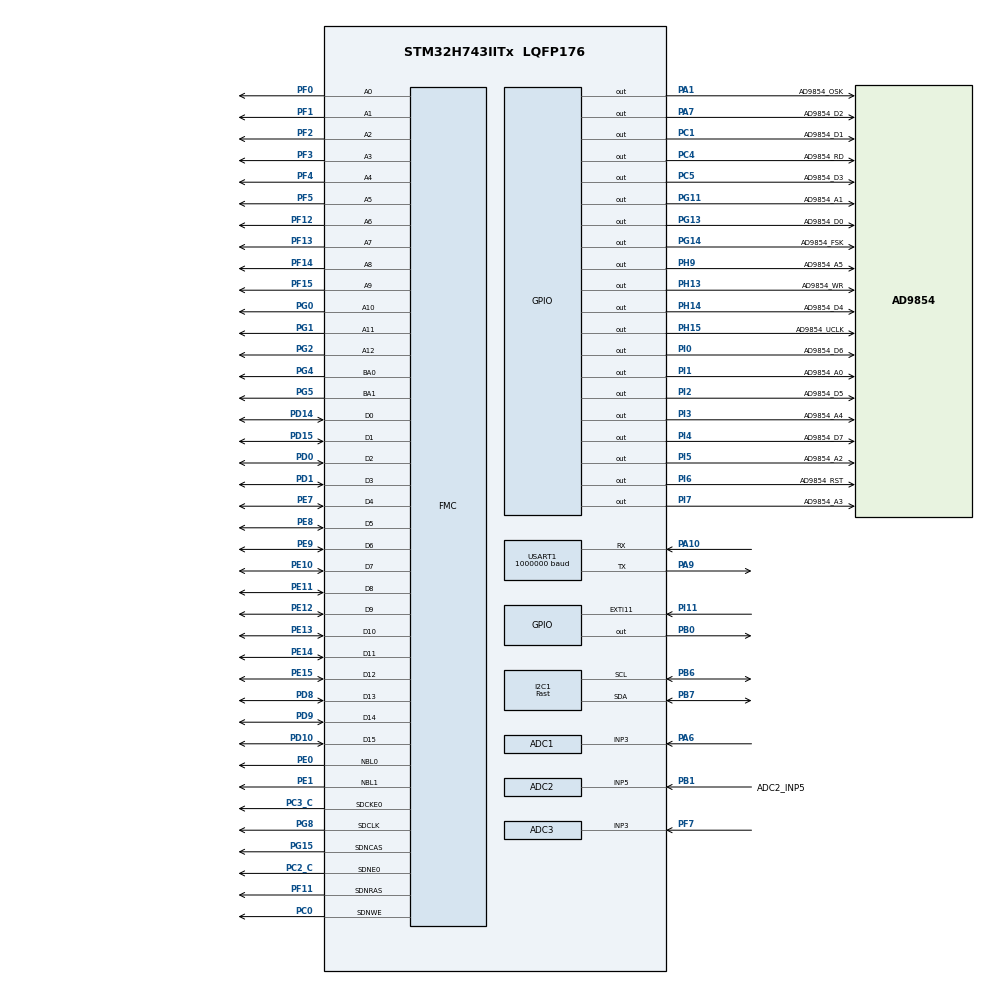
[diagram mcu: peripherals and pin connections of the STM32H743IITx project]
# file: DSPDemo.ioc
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ADC1.Channel-1\#ChannelRegularConversion=ADC_CHANNEL_3
ADC1.ConversionDataManagement=ADC_CONVERSIONDATA_DMA_CIRCULAR
ADC1.ExternalTrigConv=ADC_EXTERNALTRIG_EXT_IT11
ADC1.ExternalTrigConvEdge=ADC_EXTERNALTRIGCONVEDGE_RISING
ADC1.NbrOfConversion=1
ADC1.NbrOfConversionFlag=1
ADC1.OffsetNumber-1\#ChannelRegularConversion=ADC_OFFSET_NONE
ADC1.OffsetSignedSaturation-1\#ChannelRegularConversion=DISABLE
ADC1.Rank-1\#ChannelRegularConversion=1
ADC1.SamplingTime-1\#ChannelRegularConversion=ADC_SAMPLETIME_1CYCLE_5
ADC1.master=1
ADC2.Channel-0\#ChannelRegularConversion=ADC_CHANNEL_5
ADC2.ConversionDataManagement=ADC_CONVERSIONDATA_DMA_CIRCULAR
ADC2.NbrOfConversionFlag=1
ADC2.OffsetNumber-0\#ChannelRegularConversion=ADC_OFFSET_NONE
ADC2.OffsetSignedSaturation-0\#ChannelRegularConversion=DISABLE
ADC2.Overrun=ADC_OVR_DATA_PRESERVED
ADC2.Rank-0\#ChannelRegularConversion=1
ADC2.SamplingTime-0\#ChannelRegularConversion=ADC_SAMPLETIME_1CYCLE_5
ADC3.Channel-0\#ChannelRegularConversion=ADC_CHANNEL_3
ADC3.ConversionDataManagement=ADC_CONVERSIONDATA_DMA_CIRCULAR
ADC3.NbrOfConversionFlag=1
ADC3.OffsetNumber-0\#ChannelRegularConversion=ADC_OFFSET_NONE
ADC3.OffsetSignedSaturation-0\#ChannelRegularConversion=DISABLE
ADC3.Overrun=ADC_OVR_DATA_PRESERVED
ADC3.Rank-0\#ChannelRegularConversion=1
ADC3.SamplingTime-0\#ChannelRegularConversion=ADC_SAMPLETIME_1CYCLE_5
CORTEX_M7.AccessPermission-Cortex_Memory_Protection_Unit_Region0_Settings=MPU_REGION_FULL_ACCESS
CORTEX_M7.AccessPermission-Cortex_Memory_Protection_Unit_Region1_Settings=MPU_REGION_FULL_ACCESS
CORTEX_M7.AccessPermission-Cortex_Memory_Protection_Unit_Region2_Settings=MPU_REGION_FULL_ACCESS
CORTEX_M7.AccessPermission-Cortex_Memory_Protection_Unit_Region3_Settings=MPU_REGION_FULL_ACCESS
CORTEX_M7.AccessPermission-Cortex_Memory_Protection_Unit_Region4_Settings=MPU_REGION_FULL_ACCESS
CORTEX_M7.AccessPermission-Cortex_Memory_Protection_Unit_Region5_Settings=MPU_REGION_FULL_ACCESS
CORTEX_M7.AccessPermission-Cortex_Memory_Protection_Unit_Region6_Settings=MPU_REGION_FULL_ACCESS
CORTEX_M7.BaseAddress-Cortex_Memory_Protection_Unit_Region0_Settings=0x20000000
CORTEX_M7.BaseAddress-Cortex_Memory_Protection_Unit_Region1_Settings=0x24000000
CORTEX_M7.BaseAddress-Cortex_Memory_Protection_Unit_Region2_Settings=0x30000000
CORTEX_M7.BaseAddress-Cortex_Memory_Protection_Unit_Region3_Settings=0x38000000
CORTEX_M7.BaseAddress-Cortex_Memory_Protection_Unit_Region4_Settings=0x60000000
CORTEX_M7.BaseAddress-Cortex_Memory_Protection_Unit_Region5_Settings=0xC0000000
CORTEX_M7.BaseAddress-Cortex_Memory_Protection_Unit_Region6_Settings=0x80000000
CORTEX_M7.CPU_DCache=Enabled
CORTEX_M7.CPU_ICache=Enabled
CORTEX_M7.DisableExec-Cortex_Memory_Protection_Unit_Region6_Settings=MPU_INSTRUCTION_ACCESS_DISABLE
CORTEX_M7.Enable-Cortex_Memory_Protection_Unit_Region0_Settings=MPU_REGION_ENABLE
CORTEX_M7.Enable-Cortex_Memory_Protection_Unit_Region1_Settings=MPU_REGION_ENABLE
CORTEX_M7.Enable-Cortex_Memory_Protection_Unit_Region2_Settings=MPU_REGION_ENABLE
CORTEX_M7.Enable-Cortex_Memory_Protection_Unit_Region3_Settings=MPU_REGION_ENABLE
CORTEX_M7.Enable-Cortex_Memory_Protection_Unit_Region4_Settings=MPU_REGION_ENABLE
CORTEX_M7.Enable-Cortex_Memory_Protection_Unit_Region5_Settings=MPU_REGION_ENABLE
CORTEX_M7.Enable-Cortex_Memory_Protection_Unit_Region6_Settings=MPU_REGION_ENABLE
CORTEX_M7.Enable-Cortex_Memory_Protection_Unit_Region7_Settings=__NULL
CORTEX_M7.IsBufferable-Cortex_Memory_Protection_Unit_Region0_Settings=MPU_ACCESS_BUFFERABLE
CORTEX_M7.IsBufferable-Cortex_Memory_Protection_Unit_Region1_Settings=MPU_ACCESS_NOT_BUFFERABLE
CORTEX_M7.IsBufferable-Cortex_Memory_Protection_Unit_Region2_Settings=MPU_ACCESS_BUFFERABLE
CORTEX_M7.IsBufferable-Cortex_Memory_Protection_Unit_Region3_Settings=MPU_ACCESS_BUFFERABLE
CORTEX_M7.IsBufferable-Cortex_Memory_Protection_Unit_Region4_Settings=MPU_ACCESS_NOT_BUFFERABLE
CORTEX_M7.IsBufferable-Cortex_Memory_Protection_Unit_Region5_Settings=MPU_ACCESS_NOT_BUFFERABLE
CORTEX_M7.IsBufferable-Cortex_Memory_Protection_Unit_Region6_Settings=MPU_ACCESS_NOT_BUFFERABLE
CORTEX_M7.IsCacheable-Cortex_Memory_Protection_Unit_Region0_Settings=MPU_ACCESS_CACHEABLE
CORTEX_M7.IsCacheable-Cortex_Memory_Protection_Unit_Region1_Settings=MPU_ACCESS_CACHEABLE
CORTEX_M7.IsCacheable-Cortex_Memory_Protection_Unit_Region2_Settings=MPU_ACCESS_CACHEABLE
CORTEX_M7.IsCacheable-Cortex_Memory_Protection_Unit_Region3_Settings=MPU_ACCESS_CACHEABLE
CORTEX_M7.IsCacheable-Cortex_Memory_Protection_Unit_Region4_Settings=MPU_ACCESS_NOT_CACHEABLE
CORTEX_M7.IsCacheable-Cortex_Memory_Protection_Unit_Region5_Settings=MPU_ACCESS_NOT_CACHEABLE
CORTEX_M7.IsCacheable-Cortex_Memory_Protection_Unit_Region6_Settings=MPU_ACCESS_CACHEABLE
CORTEX_M7.IsShareable-Cortex_Memory_Protection_Unit_Region1_Settings=MPU_ACCESS_SHAREABLE
CORTEX_M7.IsShareable-Cortex_Memory_Protection_Unit_Region2_Settings=MPU_ACCESS_NOT_SHAREABLE
CORTEX_M7.MPU_Control=MPU_PRIVILEGED_DEFAULT
CORTEX_M7.Size-Cortex_Memory_Protection_Unit_Region0_Settings=MPU_REGION_SIZE_128KB
CORTEX_M7.Size-Cortex_Memory_Protection_Unit_Region1_Settings=MPU_REGION_SIZE_512KB
CORTEX_M7.Size-Cortex_Memory_Protection_Unit_Region2_Settings=MPU_REGION_SIZE_512KB
CORTEX_M7.Size-Cortex_Memory_Protection_Unit_Region3_Settings=MPU_REGION_SIZE_64KB
CORTEX_M7.Size-Cortex_Memory_Protection_Unit_Region4_Settings=MPU_REGION_SIZE_256MB
CORTEX_M7.Size-Cortex_Memory_Protection_Unit_Region5_Settings=MPU_REGION_SIZE_32MB
CORTEX_M7.Size-Cortex_Memory_Protection_Unit_Region6_Settings=MPU_REGION_SIZE_256MB
CORTEX_M7.default_mode_Activation=0
Dma.ADC1.0.Direction=DMA_PERIPH_TO_MEMORY
Dma.ADC1.0.EventEnable=DISABLE
Dma.ADC1.0.FIFOMode=DMA_FIFOMODE_DISABLE
Dma.ADC1.0.Instance=DMA1_Stream2
Dma.ADC1.0.MemDataAlignment=DMA_MDATAALIGN_HALFWORD
Dma.ADC1.0.MemInc=DMA_MINC_ENABLE
Dma.ADC1.0.Mode=DMA_CIRCULAR
Dma.ADC1.0.PeriphDataAlignment=DMA_PDATAALIGN_HALFWORD
Dma.ADC1.0.PeriphInc=DMA_PINC_DISABLE
Dma.ADC1.0.Polarity=HAL_DMAMUX_REQ_GEN_RISING
Dma.ADC1.0.Priority=DMA_PRIORITY_LOW
Dma.ADC1.0.RequestNumber=1
Dma.ADC1.0.SignalID=NONE
Dma.ADC1.0.SyncEnable=DISABLE
Dma.ADC1.0.SyncPolarity=HAL_DMAMUX_SYNC_NO_EVENT
Dma.ADC1.0.SyncRequestNumber=1
Dma.ADC1.0.SyncSignalID=NONE
Dma.ADC2.1.Direction=DMA_PERIPH_TO_MEMORY
Dma.ADC2.1.EventEnable=DISABLE
Dma.ADC2.1.FIFOMode=DMA_FIFOMODE_DISABLE
Dma.ADC2.1.Instance=DMA1_Stream3
Dma.ADC2.1.MemDataAlignment=DMA_MDATAALIGN_HALFWORD
Dma.ADC2.1.MemInc=DMA_MINC_ENABLE
Dma.ADC2.1.Mode=DMA_CIRCULAR
Dma.ADC2.1.PeriphDataAlignment=DMA_PDATAALIGN_HALFWORD
Dma.ADC2.1.PeriphInc=DMA_PINC_DISABLE
Dma.ADC2.1.Polarity=HAL_DMAMUX_REQ_GEN_RISING
Dma.ADC2.1.Priority=DMA_PRIORITY_LOW
Dma.ADC2.1.RequestNumber=1
Dma.ADC2.1.SignalID=NONE
Dma.ADC2.1.SyncEnable=DISABLE
Dma.ADC2.1.SyncPolarity=HAL_DMAMUX_SYNC_NO_EVENT
Dma.ADC2.1.SyncRequestNumber=1
Dma.ADC2.1.SyncSignalID=NONE
Dma.ADC3.2.Direction=DMA_PERIPH_TO_MEMORY
Dma.ADC3.2.EventEnable=DISABLE
Dma.ADC3.2.FIFOMode=DMA_FIFOMODE_DISABLE
Dma.ADC3.2.Instance=DMA1_Stream4
Dma.ADC3.2.MemDataAlignment=DMA_MDATAALIGN_HALFWORD
Dma.ADC3.2.MemInc=DMA_MINC_ENABLE
Dma.ADC3.2.Mode=DMA_CIRCULAR
Dma.ADC3.2.PeriphDataAlignment=DMA_PDATAALIGN_HALFWORD
Dma.ADC3.2.PeriphInc=DMA_PINC_DISABLE
Dma.ADC3.2.Polarity=HAL_DMAMUX_REQ_GEN_RISING
Dma.ADC3.2.Priority=DMA_PRIORITY_LOW
Dma.ADC3.2.RequestNumber=1
Dma.ADC3.2.SignalID=NONE
Dma.ADC3.2.SyncEnable=DISABLE
Dma.ADC3.2.SyncPolarity=HAL_DMAMUX_SYNC_NO_EVENT
Dma.ADC3.2.SyncRequestNumber=1
Dma.ADC3.2.SyncSignalID=NONE
Dma.Request0=ADC1
Dma.Request1=ADC2
Dma.Request2=ADC3
FMC.CASLatency1=FMC_SDRAM_CAS_LATENCY_3
FMC.ColumnBitsNumber1=FMC_SDRAM_COLUMN_BITS_NUM_9
FMC.ExitSelfRefreshDelay1=8
FMC.LoadToActiveDelay1=2
FMC.RCDDelay1=2
FMC.RPDelay1=2
FMC.ReadBurst1=FMC_SDRAM_RBURST_ENABLE
FMC.ReadPipeDelay1=FMC_SDRAM_RPIPE_DELAY_1
FMC.RowCycleDelay1=6
FMC.SDClockPeriod1=FMC_SDRAM_CLOCK_PERIOD_2
FMC.SelfRefreshTime1=6
FMC.WriteRecoveryTime1=4
I2C1.AddressingMode=I2C_ADDRESSINGMODE_7BIT
I2C1.I2C_Speed_Mode=I2C_Fast
I2C1.Timing=0x009034B6
Mcu.Family=STM32H7
Mcu.Name=STM32H743IITx
Mcu.Package=LQFP176
NVIC.DMA1_Stream2_IRQn=true\:1\:0\:true\:false\:true\:true\:true\:true
NVIC.DMA1_Stream3_IRQn=true\:1\:0\:true\:false\:true\:true\:true\:true
NVIC.DMA1_Stream4_IRQn=true\:1\:0\:true\:false\:true\:true\:true\:true
NVIC.EXTI15_10_IRQn=true\:1\:0\:true\:false\:true\:true\:true\:true
NVIC.PriorityGroup=NVIC_PRIORITYGROUP_4
NVIC.USART1_IRQn=true\:0\:0\:true\:false\:true\:true\:true\:true
PA1.GPIO_Label=AD9854_OSK
PA1.Signal=GPIO_Output
PA10.Mode=Asynchronous
PA10.Signal=USART1_RX
PA13\ (JTMS/SWDIO).Mode=Serial_Wire
PA13\ (JTMS/SWDIO).Signal=DEBUG_JTMS-SWDIO
PA14\ (JTCK/SWCLK).Mode=Serial_Wire
PA14\ (JTCK/SWCLK).Signal=DEBUG_JTCK-SWCLK
PA6.GPIO_Mode=GPIO_MODE_ANALOG
PA6.Signal=ADCx_INP3
PA7.GPIO_Label=AD9854_D2
PA7.Signal=GPIO_Output
PA9.Mode=Asynchronous
PA9.Signal=USART1_TX
PB0.GPIO_PuPd=GPIO_PULLUP
PB0.GPIO_Speed=GPIO_SPEED_FREQ_MEDIUM
PB0.PinState=GPIO_PIN_SET
PB0.Signal=GPIO_Output
PB1.GPIO_Label=ADC2_INP5
PB1.Signal=ADCx_INP5
PB12.Signal=SPI2_NSS
PB6.Mode=I2C
PB6.Signal=I2C1_SCL
PB7.GPIO_Speed=GPIO_SPEED_FREQ_LOW
PB7.Mode=I2C
PB7.Signal=I2C1_SDA
PC0.Signal=FMC_SDNWE
PC1.GPIO_Label=AD9854_D1
PC1.Signal=GPIO_Output
PC14-OSC32_IN\ (OSC32_IN).Mode=LSE-External-Oscillator
PC14-OSC32_IN\ (OSC32_IN).Signal=RCC_OSC32_IN
PC15-OSC32_OUT\ (OSC32_OUT).Mode=LSE-External-Oscillator
PC15-OSC32_OUT\ (OSC32_OUT).Signal=RCC_OSC32_OUT
PC2_C.Mode=SdramChipSelect1_1
PC2_C.Signal=FMC_SDNE0
PC3_C.Mode=SdramChipSelect1_1
PC3_C.Signal=FMC_SDCKE0
PC4.GPIO_Label=AD9854_RD
PC4.Signal=GPIO_Output
PC5.GPIO_Label=AD9854_D3
PC5.Signal=GPIO_Output
PD0.Signal=FMC_D2_DA2
PD1.Signal=FMC_D3_DA3
PD10.Signal=FMC_D15_DA15
PD14.Signal=FMC_D0_DA0
PD15.Signal=FMC_D1_DA1
PD8.Signal=FMC_D13_DA13
PD9.Signal=FMC_D14_DA14
PE0.Signal=FMC_NBL0
PE1.Signal=FMC_NBL1
PE10.Signal=FMC_D7_DA7
PE11.Signal=FMC_D8_DA8
PE12.Signal=FMC_D9_DA9
PE13.Signal=FMC_D10_DA10
PE14.Signal=FMC_D11_DA11
PE15.Signal=FMC_D12_DA12
PE7.Signal=FMC_D4_DA4
PE8.Signal=FMC_D5_DA5
PE9.Signal=FMC_D6_DA6
PF0.Signal=FMC_A0
PF1.Signal=FMC_A1
PF11.Signal=FMC_SDNRAS
PF12.Signal=FMC_A6
PF13.Signal=FMC_A7
PF14.Signal=FMC_A8
PF15.Signal=FMC_A9
PF2.Signal=FMC_A2
PF3.Signal=FMC_A3
PF4.Signal=FMC_A4
PF5.Signal=FMC_A5
PF7.Mode=IN3-Single-Ended
PF7.Signal=ADC3_INP3
PG0.Signal=FMC_A10
PG1.Signal=FMC_A11
PG11.GPIO_Label=AD9854_A1
PG11.Signal=GPIO_Output
PG13.GPIO_Label=AD9854_D0
PG13.Signal=GPIO_Output
PG14.GPIO_Label=AD9854_FSK
PG14.Signal=GPIO_Output
PG15.Signal=FMC_SDNCAS
PG2.Signal=FMC_A12
PG4.Signal=FMC_A14_BA0
PG5.Signal=FMC_A15_BA1
PG8.Signal=FMC_SDCLK
PH0-OSC_IN\ (PH0).Mode=HSE-External-Oscillator
PH0-OSC_IN\ (PH0).Signal=RCC_OSC_IN
PH1-OSC_OUT\ (PH1).Mode=HSE-External-Oscillator
PH1-OSC_OUT\ (PH1).Signal=RCC_OSC_OUT
PH13.GPIO_Label=AD9854_WR
PH13.Signal=GPIO_Output
PH14.GPIO_Label=AD9854_D4
PH14.Signal=GPIO_Output
PH15.GPIO_Label=AD9854_UCLK
PH15.Signal=GPIO_Output
PH9.GPIO_Label=AD9854_A5
PH9.Signal=GPIO_Output
PI0.GPIO_Label=AD9854_D6
PI0.Signal=GPIO_Output
PI1.GPIO_Label=AD9854_A0
PI1.Signal=GPIO_Output
PI11.Signal=GPXTI11
PI2.GPIO_Label=AD9854_D5
PI2.Signal=GPIO_Output
PI3.GPIO_Label=AD9854_A4
PI3.Signal=GPIO_Output
PI4.GPIO_Label=AD9854_D7
PI4.Signal=GPIO_Output
PI5.GPIO_Label=AD9854_A2
PI5.Signal=GPIO_Output
PI6.GPIO_Label=AD9854_RST
PI6.Signal=GPIO_Output
PI7.GPIO_Label=AD9854_A3
PI7.Signal=GPIO_Output
ProjectManager.HeapSize=0x200
ProjectManager.StackSize=0x400
ProjectManager.TargetToolchain=MDK-ARM V5.32
RCC.ADCFreq_Value=100000000
RCC.APB1Freq_Value=100000000
RCC.APB2Freq_Value=100000000
RCC.APB3Freq_Value=100000000
RCC.APB4Freq_Value=100000000
RCC.CKPERSourceSelection=RCC_CLKPSOURCE_HSE
RCC.CortexFreq_Value=400000000
RCC.D1PPRE=RCC_APB3_DIV2
RCC.D2PPRE1=RCC_APB1_DIV2
RCC.D2PPRE2=RCC_APB2_DIV2
RCC.D3PPRE=RCC_APB4_DIV2
RCC.DIVM1=2
RCC.DIVM2=5
RCC.DIVM3=5
RCC.DIVN1=64
RCC.DIVN2=100
RCC.DIVN3=50
RCC.DIVP2=5
RCC.DIVP3=10
RCC.DIVQ1=4
RCC.DIVQ2=4
RCC.DIVR2=4
RCC.FMCCLockSelection=RCC_FMCCLKSOURCE_PLL2
RCC.HCLKFreq_Value=200000000
RCC.HPRE=RCC_HCLK_DIV2
RCC.PLL2FRACN=0
RCC.PLL3FRACN=0
RCC.PLLFRACN=0
RCC.PLLSourceVirtual=RCC_PLLSOURCE_HSE
RCC.SPI123CLockSelection=RCC_SPI123CLKSOURCE_PLL3
RCC.SYSCLKFreq_VALUE=400000000
RCC.SYSCLKSource=RCC_SYSCLKSOURCE_PLLCLK
RCC.USBFreq_Value=200000000
SH.ADCx_INP3.0=ADC1_INP3,IN3-Single-Ended
SH.ADCx_INP5.0=ADC2_INP5,IN5-Single-Ended
SH.FMC_A0.0=FMC_A0,13b-sda1
SH.FMC_A1.0=FMC_A1,13b-sda1
SH.FMC_A10.0=FMC_A10,13b-sda1
SH.FMC_A11.0=FMC_A11,13b-sda1
SH.FMC_A12.0=FMC_A12,13b-sda1
SH.FMC_A14_BA0.0=FMC_BA0,FourSdramBanks1
SH.FMC_A15_BA1.0=FMC_BA1,FourSdramBanks1
SH.FMC_A2.0=FMC_A2,13b-sda1
SH.FMC_A3.0=FMC_A3,13b-sda1
SH.FMC_A4.0=FMC_A4,13b-sda1
SH.FMC_A5.0=FMC_A5,13b-sda1
SH.FMC_A6.0=FMC_A6,13b-sda1
SH.FMC_A7.0=FMC_A7,13b-sda1
SH.FMC_A8.0=FMC_A8,13b-sda1
SH.FMC_A9.0=FMC_A9,13b-sda1
SH.FMC_D0_DA0.0=FMC_D0,sd-16b-d1
SH.FMC_D10_DA10.0=FMC_D10,sd-16b-d1
SH.FMC_D11_DA11.0=FMC_D11,sd-16b-d1
SH.FMC_D12_DA12.0=FMC_D12,sd-16b-d1
SH.FMC_D13_DA13.0=FMC_D13,sd-16b-d1
SH.FMC_D14_DA14.0=FMC_D14,sd-16b-d1
SH.FMC_D15_DA15.0=FMC_D15,sd-16b-d1
SH.FMC_D1_DA1.0=FMC_D1,sd-16b-d1
SH.FMC_D2_DA2.0=FMC_D2,sd-16b-d1
SH.FMC_D3_DA3.0=FMC_D3,sd-16b-d1
SH.FMC_D4_DA4.0=FMC_D4,sd-16b-d1
SH.FMC_D5_DA5.0=FMC_D5,sd-16b-d1
SH.FMC_D6_DA6.0=FMC_D6,sd-16b-d1
SH.FMC_D7_DA7.0=FMC_D7,sd-16b-d1
SH.FMC_D8_DA8.0=FMC_D8,sd-16b-d1
SH.FMC_D9_DA9.0=FMC_D9,sd-16b-d1
SH.FMC_NBL0.0=FMC_NBL0,Sd2ByteEnable1
SH.FMC_NBL1.0=FMC_NBL1,Sd2ByteEnable1
SH.FMC_SDCLK.0=FMC_SDCLK,13b-sda1
SH.FMC_SDNCAS.0=FMC_SDNCAS,13b-sda1
SH.FMC_SDNRAS.0=FMC_SDNRAS,13b-sda1
SH.FMC_SDNWE.0=FMC_SDNWE,13b-sda1
USART1.BaudRate=1000000
USART1.VirtualMode-Asynchronous=VM_ASYNC
VP_MEMORYMAP_VS_MEMORYMAP.Mode=CurAppReg
board=custom

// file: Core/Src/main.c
/* USER CODE BEGIN Header */
/**
  ******************************************************************************
  * @file           : main.c
  * @brief          : Main program body
  ******************************************************************************
  * @attention
  *
  * Copyright (c) 2025 STMicroelectronics.
  * All rights reserved.
  *
  * This software is licensed under terms that can be found in the LICENSE file
  * in the root directory of this software component.
  * If no LICENSE file comes with this software, it is provided AS-IS.
  *
  ******************************************************************************
  */
/* USER CODE END Header */
#include "main.h"
#include "adc.h"
#include "dma.h"
#include "i2c.h"
#include "usart.h"
#include "gpio.h"
#include "fmc.h"

/* USER CODE BEGIN Includes */
#include "led.h"
#include "LMS_norm.h"
#include "BSP_ADC.H"
#include "stdio.h"
#include "thd.h"
#include "SI5351.h"
#include "AD9854_Parallel.h"
/* USER CODE END Includes */

/* USER CODE BEGIN PV */
volatile uint8_t key = 0;

/* USER CODE END PV */

void SystemClock_Config(void);
void PeriphCommonClock_Config(void);
static void MPU_Config(void);

/* USER CODE BEGIN 0 */
uint32_t freq = 1000;
/* USER CODE END 0 */

int main(void)
{

  /* USER CODE BEGIN 1 */
 uint16_t len ;//数据长度
  /* USER CODE END 1 */

  /* MPU Configuration--------------------------------------------------------*/
  MPU_Config();

  /* Enable the CPU Cache */

  /* Enable I-Cache---------------------------------------------------------*/
  SCB_EnableICache();

  /* Enable D-Cache---------------------------------------------------------*/
  SCB_EnableDCache();

  /* MCU Configuration--------------------------------------------------------*/

  /* Reset of all peripherals, Initializes the Flash interface and the Systick. */
  HAL_Init();

  /* Configure the system clock */
  SystemClock_Config();

  /* Configure the peripherals common clocks */
  PeriphCommonClock_Config();

  /* Initialize all configured peripherals */
  MX_GPIO_Init();
  MX_DMA_Init();
  MX_USART1_UART_Init();
  MX_ADC1_Init();
  MX_I2C1_Init();
  MX_ADC2_Init();
  MX_ADC3_Init();
  MX_FMC_Init();
  /* USER CODE BEGIN 2 */
  simply819_2khz();
 HAL_NVIC_EnableIRQ(EXTI15_10_IRQn);
	adc_init();

   freq =1000;
   AD9854_InitSingle();
   AD9854_SetSine(409600,4095); //初始化1khz正弦波
  /* USER CODE END 2 */

  /* Infinite loop */
  while (1)
  {

    /* USER CODE BEGIN 3 */

       if(USART_RX_STA&0x8000)
      {
        len=USART_RX_STA&0x3fff;//得到此次接收到的数据长度，具体可以看看源码，非常有意思
        //uint16_t*p = (uint16_t*)USART_RX_BUF;
        if(USART_RX_BUF[0] == 0xEE && USART_RX_BUF[1] == 0xFF)  //普通判断模式
        {
            FSK_mode = 0;
        }
        else if(USART_RX_BUF[0] == 0xCC && USART_RX_BUF[1] == 0xDD)//扫频模式
        {
            FSK_mode = 1;
        }
			  USART_RX_STA=0;
      }
      else
      {
         __NOP();//这部分也很要必要，否则会进不来判断，这部分就相当于空
      }

    if(start_flag == 1 && (FSK_mode == 1))//扫频   1000-500k,步进100hz
    {
      freq = freq + 100;
      AD9854_SetSine(freq,4095);
      if(freq>=500000)
      {
         freq = 1000;
         FSK_mode = 0;
      }

       start_flag = 0;
    }
    else if((FSK_mode == 0))
    {
      freq = 1000;
    }
    else
    {
      __nop();
    }
    adc_dsp_working();

  }
  /* USER CODE END 3 */
}

void SystemClock_Config(void)
{
  RCC_OscInitTypeDef RCC_OscInitStruct = {0};
  RCC_ClkInitTypeDef RCC_ClkInitStruct = {0};

  /** Supply configuration update enable
  */
  HAL_PWREx_ConfigSupply(PWR_LDO_SUPPLY);

  /** Configure the main internal regulator output voltage
  */
  __HAL_PWR_VOLTAGESCALING_CONFIG(PWR_REGULATOR_VOLTAGE_SCALE1);

  while(!__HAL_PWR_GET_FLAG(PWR_FLAG_VOSRDY)) {}

  /** Initializes the RCC Oscillators according to the specified parameters
  * in the RCC_OscInitTypeDef structure.
  */
  RCC_OscInitStruct.OscillatorType = RCC_OSCILLATORTYPE_HSE;
  RCC_OscInitStruct.HSEState = RCC_HSE_ON;
  RCC_OscInitStruct.PLL.PLLState = RCC_PLL_ON;
  RCC_OscInitStruct.PLL.PLLSource = RCC_PLLSOURCE_HSE;
  RCC_OscInitStruct.PLL.PLLM = 2;
  RCC_OscInitStruct.PLL.PLLN = 64;
  RCC_OscInitStruct.PLL.PLLP = 2;
  RCC_OscInitStruct.PLL.PLLQ = 4;
  RCC_OscInitStruct.PLL.PLLR = 2;
  RCC_OscInitStruct.PLL.PLLRGE = RCC_PLL1VCIRANGE_3;
  RCC_OscInitStruct.PLL.PLLVCOSEL = RCC_PLL1VCOWIDE;
  RCC_OscInitStruct.PLL.PLLFRACN = 0;
  if (HAL_RCC_OscConfig(&RCC_OscInitStruct) != HAL_OK)
  {
    Error_Handler();
  }

  /** Initializes the CPU, AHB and APB buses clocks
  */
  RCC_ClkInitStruct.ClockType = RCC_CLOCKTYPE_HCLK|RCC_CLOCKTYPE_SYSCLK
                              |RCC_CLOCKTYPE_PCLK1|RCC_CLOCKTYPE_PCLK2
                              |RCC_CLOCKTYPE_D3PCLK1|RCC_CLOCKTYPE_D1PCLK1;
  RCC_ClkInitStruct.SYSCLKSource = RCC_SYSCLKSOURCE_PLLCLK;
  RCC_ClkInitStruct.SYSCLKDivider = RCC_SYSCLK_DIV1;
  RCC_ClkInitStruct.AHBCLKDivider = RCC_HCLK_DIV2;
  RCC_ClkInitStruct.APB3CLKDivider = RCC_APB3_DIV2;
  RCC_ClkInitStruct.APB1CLKDivider = RCC_APB1_DIV2;
  RCC_ClkInitStruct.APB2CLKDivider = RCC_APB2_DIV2;
  RCC_ClkInitStruct.APB4CLKDivider = RCC_APB4_DIV2;

  if (HAL_RCC_ClockConfig(&RCC_ClkInitStruct, FLASH_LATENCY_2) != HAL_OK)
  {
    Error_Handler();
  }
}

void PeriphCommonClock_Config(void)
{
  RCC_PeriphCLKInitTypeDef PeriphClkInitStruct = {0};

  /** Initializes the peripherals clock
  */
  PeriphClkInitStruct.PeriphClockSelection = RCC_PERIPHCLK_FMC|RCC_PERIPHCLK_ADC;
  PeriphClkInitStruct.PLL2.PLL2M = 5;
  PeriphClkInitStruct.PLL2.PLL2N = 100;
  PeriphClkInitStruct.PLL2.PLL2P = 5;
  PeriphClkInitStruct.PLL2.PLL2Q = 4;
  PeriphClkInitStruct.PLL2.PLL2R = 4;
  PeriphClkInitStruct.PLL2.PLL2RGE = RCC_PLL2VCIRANGE_2;
  PeriphClkInitStruct.PLL2.PLL2VCOSEL = RCC_PLL2VCOWIDE;
  PeriphClkInitStruct.PLL2.PLL2FRACN = 0;
  PeriphClkInitStruct.FmcClockSelection = RCC_FMCCLKSOURCE_PLL2;
  PeriphClkInitStruct.AdcClockSelection = RCC_ADCCLKSOURCE_PLL2;
  if (HAL_RCCEx_PeriphCLKConfig(&PeriphClkInitStruct) != HAL_OK)
  {
    Error_Handler();
  }
}

 /* MPU Configuration */

void MPU_Config(void)
{
  MPU_Region_InitTypeDef MPU_InitStruct = {0};

  /* Disables the MPU */
  HAL_MPU_Disable();

  /** Initializes and configures the Region and the memory to be protected
  */
  MPU_InitStruct.Enable = MPU_REGION_ENABLE;
  MPU_InitStruct.Number = MPU_REGION_NUMBER0;
  MPU_InitStruct.BaseAddress = 0x20000000;
  MPU_InitStruct.Size = MPU_REGION_SIZE_128KB;
  MPU_InitStruct.SubRegionDisable = 0x0;
  MPU_InitStruct.TypeExtField = MPU_TEX_LEVEL0;
  MPU_InitStruct.AccessPermission = MPU_REGION_FULL_ACCESS;
  MPU_InitStruct.DisableExec = MPU_INSTRUCTION_ACCESS_ENABLE;
  MPU_InitStruct.IsShareable = MPU_ACCESS_NOT_SHAREABLE;
  MPU_InitStruct.IsCacheable = MPU_ACCESS_CACHEABLE;
  MPU_InitStruct.IsBufferable = MPU_ACCESS_BUFFERABLE;

  HAL_MPU_ConfigRegion(&MPU_InitStruct);

  /** Initializes and configures the Region and the memory to be protected
  */
  MPU_InitStruct.Number = MPU_REGION_NUMBER1;
  MPU_InitStruct.BaseAddress = 0x24000000;
  MPU_InitStruct.Size = MPU_REGION_SIZE_512KB;
  MPU_InitStruct.IsShareable = MPU_ACCESS_SHAREABLE;
  MPU_InitStruct.IsBufferable = MPU_ACCESS_NOT_BUFFERABLE;

  HAL_MPU_ConfigRegion(&MPU_InitStruct);

  /** Initializes and configures the Region and the memory to be protected
  */
  MPU_InitStruct.Number = MPU_REGION_NUMBER2;
  MPU_InitStruct.BaseAddress = 0x30000000;
  MPU_InitStruct.IsShareable = MPU_ACCESS_NOT_SHAREABLE;
  MPU_InitStruct.IsBufferable = MPU_ACCESS_BUFFERABLE;

  HAL_MPU_ConfigRegion(&MPU_InitStruct);

  /** Initializes and configures the Region and the memory to be protected
  */
  MPU_InitStruct.Number = MPU_REGION_NUMBER3;
  MPU_InitStruct.BaseAddress = 0x38000000;
  MPU_InitStruct.Size = MPU_REGION_SIZE_64KB;

  HAL_MPU_ConfigRegion(&MPU_InitStruct);

  /** Initializes and configures the Region and the memory to be protected
  */
  MPU_InitStruct.Number = MPU_REGION_NUMBER4;
  MPU_InitStruct.BaseAddress = 0x60000000;
  MPU_InitStruct.Size = MPU_REGION_SIZE_256MB;
  MPU_InitStruct.IsCacheable = MPU_ACCESS_NOT_CACHEABLE;
  MPU_InitStruct.IsBufferable = MPU_ACCESS_NOT_BUFFERABLE;

  HAL_MPU_ConfigRegion(&MPU_InitStruct);

  /** Initializes and configures the Region and the memory to be protected
  */
  MPU_InitStruct.Number = MPU_REGION_NUMBER5;
  MPU_InitStruct.BaseAddress = 0xC0000000;
  MPU_InitStruct.Size = MPU_REGION_SIZE_32MB;

  HAL_MPU_ConfigRegion(&MPU_InitStruct);

  /** Initializes and configures the Region and the memory to be protected
  */
  MPU_InitStruct.Number = MPU_REGION_NUMBER6;
  MPU_InitStruct.BaseAddress = 0x80000000;
  MPU_InitStruct.Size = MPU_REGION_SIZE_256MB;
  MPU_InitStruct.DisableExec = MPU_INSTRUCTION_ACCESS_DISABLE;
  MPU_InitStruct.IsCacheable = MPU_ACCESS_CACHEABLE;

  HAL_MPU_ConfigRegion(&MPU_InitStruct);
  /* Enables the MPU */
  HAL_MPU_Enable(MPU_PRIVILEGED_DEFAULT);

}

void Error_Handler(void)
{
  __disable_irq();
  while (1)
  {
  }
}
